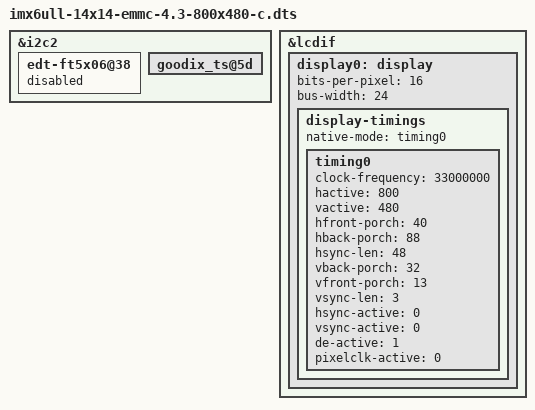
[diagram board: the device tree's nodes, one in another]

#include "imx6ull-14x14-evk-emmc.dts"

&i2c2 {
	edt-ft5x06@38 {
		status = "disabled";
	};

	goodix_ts@5d {
		status = "okay";
	};
};

&lcdif {
	display0: display {
		bits-per-pixel = <16>;
		bus-width = <24>;

		display-timings {
			native-mode = <&timing0>;
			timing0: timing0 {
			clock-frequency = <33000000>;
			hactive = <800>;
			vactive = <480>;
			hfront-porch = <40>;
			hback-porch = <88>;
			hsync-len = <48>;
			vback-porch = <32>;
			vfront-porch = <13>;
			vsync-len = <3>;

			hsync-active = <0>;
			vsync-active = <0>;
			de-active = <1>;
			pixelclk-active = <0>;
			};
		};
	};
};
